AUTOSAR XML (schema 4-3-0)
standard types defined: uint8, uint8_DataConstr
package /ComponentTypes/CanBusOffSWC
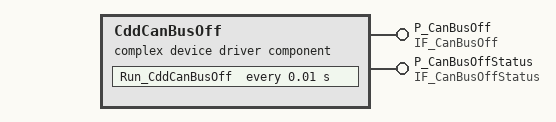
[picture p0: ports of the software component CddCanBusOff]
  complex device driver sw component type CddCanBusOff
    provide port P_CanBusOff: provided-interface=IF_CanBusOff
      provided-com-specs:
        operation=Can_BusOffIndicated, queue-length=1
        operation=CanBusOff_Begin, queue-length=1
        operation=CanBusOff_End, queue-length=1
    provide port P_CanBusOffStatus: nonqueued-sender-com-spec{data-element=DE_CanBusOffSatus, init-value=0}, provided-interface=IF_CanBusOffStatus
    behavior CddCanBusOff_InternalBehavior
      timing event CanBusOffStatus_TE: start-on-event=Run_CddCanBusOff, period=0.01
      runnable Run_CddCanBusOff
  swc implementation CddCanBusOff_Implementation: behavior=CddCanBusOff_InternalBehavior
    code-descriptors:
      code Default: artifact-descriptors=autosar-engineering-object={short-label=Default, category=SWSRC}
package /ComponentTypes/CanBusOffSWC/PortInterfaces
  client server interface IF_CanBusOff: is-service=true
    operation Can_BusOffIndicated
      arg networkHandle: type=uint8, direction=OUT, server-argument-impl-policy=USE-ARGUMENT-TYPE
    operation CanBusOff_Begin
      arg networkHandle: type=uint8, direction=INOUT, server-argument-impl-policy=USE-ARGUMENT-TYPE
    operation CanBusOff_End
      arg networkHandle: type=uint8, direction=OUT, server-argument-impl-policy=USE-ARGUMENT-TYPE
  sender receiver interface IF_CanBusOffStatus: invalidation-policy{data-element=DE_CanBusOffSatus, handle-invalid=DONT-INVALIDATE}
    data DE_CanBusOffSatus: type=uint8
